# 3061MNNIC8 register map
File version: 1.0
Registers are 32-bit, access per field, reset 0x0 unless marked. A register's access mark holds for its fields unless they carry their own. Offsets are from the block's base; [hi:lo] are bit positions.

## EFC — HIEFC_COMMON_REGS peripheral interface
Base 0x14710000
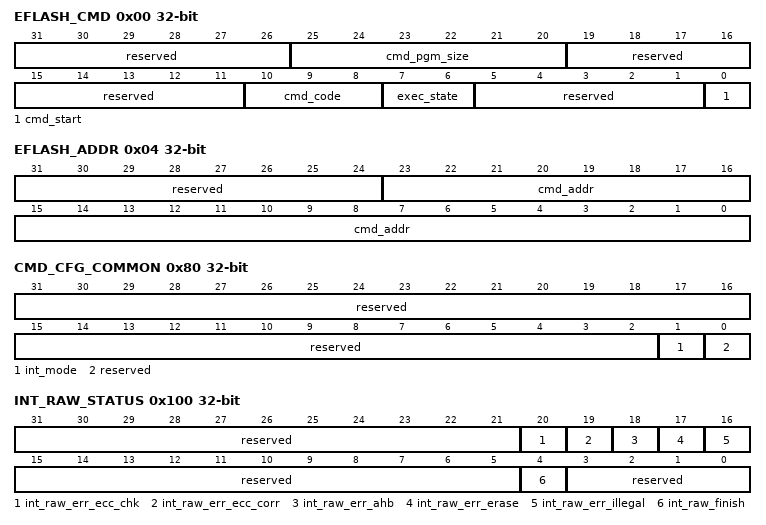
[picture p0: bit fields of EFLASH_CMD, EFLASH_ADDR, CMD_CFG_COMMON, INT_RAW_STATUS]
0x00 EFLASH_CMD — 命令寄存器。
  [31:26] reserved ro — 保留。
  [25:20] cmd_pgm_size rw — Program Size寄存器,Unit:Word（32bits）。 0x0: 2 ； 0x1: 4 ； 0x2: 8 ； … 0x0F:60； 0x10:64； others:非法值。 cmd_addr+cmd_pgm_size寻址范围不能跨越row（64Word），cmd_addr需要按64bit对齐。
  [19:11] reserved ro — 保留。
  [10:8] cmd_code rw — 操作字寄存器。 010: MAIN Program； 011: INFO Program； 100: MAIN Erase； 101: INFO Erase； 110: Mass Erase（Only Main区，不含INFO区）； others:无操作。
  [7:6] exec_state ro — CMD执行状态debug寄存器。 00（IDLE）:无操作或操作已完成； 01（RUNNING）:有操作在执行； 10（FINISH）:操作完成，但完成标示未清除(中断模式才生效)。
  [5:1] reserved ro — 保留。
  [0] cmd_start rw — CMD操作启动寄存器。 写1启动CMD操作； 写0无影响； 读1 CMD操作未完成； 读0 CMD操作完成或无操作。
0x04 EFLASH_ADDR — 地址寄存器。
  [31:24] reserved ro — 保留。
  [23:0] cmd_addr rw — Program或者Erase的起始地址寄存器，Unit:Byte（8bit）。 Main Region起始地址:0x00_0000； Information Region起始地址:0x80_0000。 注意：控制器自动忽略低2bit地址。
0x80 CMD_CFG_COMMON — CMD配置寄存器。
  [31:2] reserved ro — 保留。
  [1] int_mode rw — CMD操作方式控制寄存器。 0:轮询方式； 1:中断方式，此方式CMD操作完成后需要配置int_clr_finish清除完成标识，方可进行下一次操作。
  [0] reserved ro — 保留。
0x100 INT_RAW_STATUS ro — 中断原始状态寄存器。
  [31:21] reserved — 保留。
  [20] int_raw_err_ecc_chk — Main Region或Information Region读数据ECC检验错误原始中断寄存器。 0:无错误，或者读数据ECC检错功能未使能； 1:发生ECC检查错误。
  [19] int_raw_err_ecc_corr — Main Region或Information Region读数据ECC纠正错误原始中断寄存器。 0:无错误，或者读数据ECC纠错功能未使能； 1:发生无法纠正的ECC错误。
  [18] int_raw_err_ahb — ahb请求错误原始中断寄存器。 0:无错误； 1:ahb读请求地址超过MAIN Information Region范围或发生了ahb写请求。
  [17] int_raw_err_erase — 擦除错误原始中断状态寄存器。 0:擦除操作Verify成功； 1:擦除操作Verify失败。
  [16] int_raw_err_illegal — 非法CMD操作错误原始中断寄存器。 0:无错误； 1:存在CMD操作错误，具体错误，需要查询FLASH_STATUS寄存器。
  [15:5] reserved — 保留。
  [4] int_raw_finish — CMD操作完成原始中断寄存器。 0:无操作或者操作未完成； 1:操作已完成。
  [3:0] reserved — 保留。
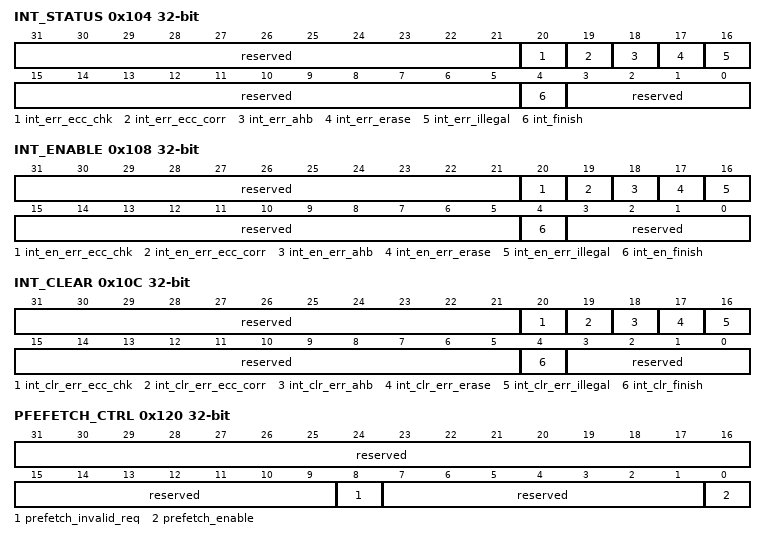
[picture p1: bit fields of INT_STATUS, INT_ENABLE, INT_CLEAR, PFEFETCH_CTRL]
0x104 INT_STATUS ro — 中断状态寄存器。
  [31:21] reserved
  [20] int_err_ecc_chk — Main Region或Information Region读数据ECC检验错误中断状态寄存器。 0：无错误，或者读数据ECC检错功能未使能 1：发生ECC检查错误
  [19] int_err_ecc_corr — Main Region或Information Region读数据ECC纠正错误中断状态寄存器。 0：无错误，或者读数据ECC纠错功能未使能 1：发生无法纠正的ECC错误
  [18] int_err_ahb — AHB请求错误中断状态寄存器。 0：无错误 1：AHB读请求地址超过Main Region或Information Region范围或发生了AHB写请求
  [17] int_err_erase — 擦除错误中断状态寄存器。 0:擦除操作Verify成功； 1:擦除操作Verify失败。
  [16] int_err_illegal — 非法CMD操作错误中断状态寄存器 0：无错误 1：存在CMD操作错误，具体错误，需要查询FLASH_STATUS寄存器
  [15:5] reserved
  [4] int_finish — CMD操作完成中断状态寄存器。 0：无操作或者操作未完成 1：操作已完成
  [3:0] reserved — 保留。
0x108 INT_ENABLE — 中断使能配置寄存器。
  [31:21] reserved ro — 保留。
  [20] int_en_err_ecc_chk rw — Main Region或Information Region读数据ECC检验错误中断使能寄存器。 0:不使能，上报原始中断，不上报中断状态，不上报CPU中断； 1:使能，上报原始中断，上报中断状态，上报CPU中断。
  [19] int_en_err_ecc_corr rw — Main Region或Information Region读数据ECC纠正错误中断使能寄存器。 0:不使能，上报原始中断，不上报中断状态，不上报CPU中断； 1:使能，上报原始中断，上报中断状态，上报CPU中断。
  [18] int_en_err_ahb rw — ahb请求错误中断使能寄存器。 0:不使能，上报原始中断，不上报中断状态，不上报CPU中断； 1:使能，上报原始中断，上报中断状态，上报CPU中断。
  [17] int_en_err_erase rw — 擦除错误中断使能寄存器。 0:不使能，上报原始中断，不上报中断状态，不上报CPU中断； 1:使能，上报原始中断，上报中断状态，上报CPU中断。
  [16] int_en_err_illegal rw — 非法CMD操作错误中断使能寄存器。 0:不使能，上报原始中断，不上报中断状态，不上报CPU中断； 1:使能，上报原始中断，上报中断状态，上报CPU中断。
  [15:5] reserved ro — 保留。
  [4] int_en_finish rw — CMD操作完成中断使能寄存器。 0:不使能，上报原始中断，不上报中断状态，不上报CPU中断； 1:使能，上报原始中断，上报中断状态，上报CPU中断。
  [3:0] reserved ro — 保留。
0x10C INT_CLEAR — 中断清除寄存器。
  [31:21] reserved ro — 保留。
  [20] int_clr_err_ecc_chk rw write-1-clears — Main Region或Information Region读数据ECC检验错误中断清除寄存器。 0:不清除； 1:清除原始中断与中断状态。
  [19] int_clr_err_ecc_corr rw write-1-clears — Main Region或Information Region读数据ECC纠正错误中断清除寄存器。 0:不清除； 1:清除原始中断与中断状态。
  [18] int_clr_err_ahb rw write-1-clears — ahb请求错误中断清除寄存器。 0:不清除； 1:清除原始中断与中断状态。
  [17] int_clr_err_erase rw write-1-clears — 擦除错误中断清除寄存器。 0:不清除； 1:清除原始中断与中断状态。
  [16] int_clr_err_illegal rw write-1-clears — 非法CMD操作错误中断清除寄存器。 0:不清除； 1:清除原始中断与中断状态。
  [15:5] reserved ro — 保留。
  [4] int_clr_finish rw write-1-clears — CMD操作完成中断清除寄存器。 0:不清除； 1:清除原始中断与中断状态。
  [3:0] reserved ro — 保留。
0x120 PFEFETCH_CTRL — 预取控制寄存器。
  [31:9] reserved ro — 保留。
  [8] prefetch_invalid_req rw — Cache数据无效请求控制寄存器。 写0:无效； 写1:请求prefetch_invalid，逻辑完成invalid后自动清除该bit； 读0:最近一次invalid请求已完成； 读1:最近一次invalid请求未完成。
  [7:1] reserved ro — 保留。
  [0] prefetch_enable rw — 预取使能控制寄存器。 0:预取使能关闭； 1:每次AHB传输完成尾地址向前预取16byte数据（以8byte对齐）。
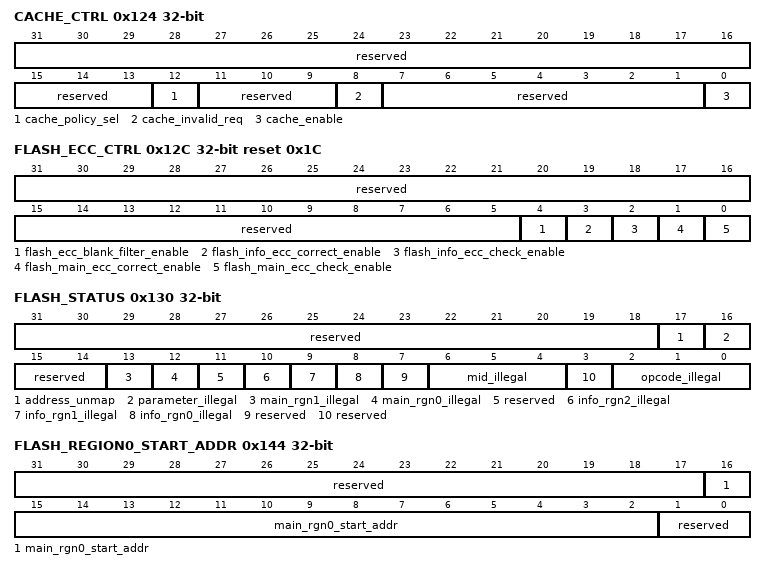
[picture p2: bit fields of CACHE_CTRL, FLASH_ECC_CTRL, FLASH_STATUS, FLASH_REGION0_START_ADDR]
0x124 CACHE_CTRL — Cache控制寄存器。
  [31:13] reserved ro — 保留。
  [12] cache_policy_sel rw — cache策略选择控制寄存器。 0:Normal Cache； 1:Branch Cache。
  [11:9] reserved ro — 保留。
  [8] cache_invalid_req rw — Cache数据无效请求控制寄存器 。 写1:请求Cache invalid，逻辑完成invalid后自动清除该bit； 写0无效； 读0:最近一次invalid请求已完成； 读1:最近一次invalid请求未完成。
  [7:1] reserved ro — 保留。
  [0] cache_enable rw — Cache使能控制寄存器。 0:Cache使能关闭； 1:Cache使能打开，AHB传输数据将会查询Cache，Cache Hit则数据从Cache获取，Cache miss则数据从eFlash获取，并将此地址数据缓存进入Cache。
0x12C FLASH_ECC_CTRL reset 0x1C — Flash ECC检错纠错使能控制寄存器。
  [31:5] reserved ro — 保留。
  [4] flash_ecc_blank_filter_enable rw — Flash未编程区域ECC屏蔽过滤使能控制（72bit全1判断为未编程区域）。 0:不使能此功能，所有read访问数据都根据flash_ecc_correct_enable、flash_ecc_check_enable配置进行相应的ECC检查或者纠正； 1:使能此功能，检查read访问数据内容，只有非全1（72bit）数据根据flash_ecc_correct_enable、flash_ecc_check_enable配置进行相应的ECC检查或者纠正。
  [3] flash_info_ecc_correct_enable rw — Flash Information region ECC纠错功能控制。 0:回读数据发生错误时，不进行ECC纠错； 1:回读数据发生1bit错误时，进行ECC纠错。
  [2] flash_info_ecc_check_enable rw — Flash Information region 检错使能控制（Program 强制ECC打开）。 0:回读数据不进行ECC检查； 1:回读数据进行ECC检查。
  [1] flash_main_ecc_correct_enable rw — Flash Main region ECC纠错功能控制。 0:回读数据发生错误时，不进行ECC纠错； 1:回读数据发生1bit错误时，进行ECC纠错。
  [0] flash_main_ecc_check_enable rw — Flash Main region检错使能控制（Program 强制ECC打开）。 0:回读数据不进行ECC检查； 1:回读数据进行ECC检查。
0x130 FLASH_STATUS ro — CMD操作FLASH状态寄存器。
  [31:18] reserved — 保留。
  [17] address_unmap — cmd操作地址是否越界指示寄存器。 0:无错误； 1:地址越界错误。
  [16] parameter_illegal — cmd操作参数是否有效指示寄存器。 0:无错误； 1:操作参数错误。
  [15:14] reserved — 保留。
  [13] main_rgn1_illegal — cmd操作main region1是否发生非法访问指示寄存器。 0:无错误； 1:Region1发生非法访问。
  [12] main_rgn0_illegal — cmd操作main region0是否发生非法访问指示寄存器。 0:无错误； 1:Region0 发送非法访问。
  [11] reserved — 保留。
  [10] info_rgn2_illegal — cmd操作info region2是否发生非法访问指示寄存器。 0:无错误； 1:info_rgn2区发生非法访问。
  [9] info_rgn1_illegal — cmd操作info region1是否发生非法访问指示寄存器。 0:无错误； 1:info_rgn1区发生非法访问。
  [8] info_rgn0_illegal — cmd操作main region0是否发生非法访问指示寄存器。 0:无错误； 1:info_rgn0区发生非法访问。
  [7] reserved — 保留。
  [6:4] mid_illegal — 发生非法访问时，cmd寄存器非法mid value。
  [3] reserved — 保留。
  [2:0] opcode_illegal — 发生非法访问时，cmd寄存器非法opcode value。
0x138 AHB_ERR_ADDR ro — AHB错误请求地址记录寄存器。
  [31:0] ahb_err_address — int_raw_err_ahb发生时，记录第一次发生ahb错误访问的地址信息，包括越界与ahb 写操作。 配置中断清除寄存器int_clr_err_ahb时，该寄存器清0，并开始记录下一次错误请求地址信息。
0x144 FLASH_REGION0_START_ADDR — MAIN REGION0起始地址。
  [31:17] reserved ro — 保留。
  [16:2] main_rgn0_start_addr rw — main_rgn0起始地址寄存器，Unit:Word（32bit）。
  [1:0] reserved ro — 保留。
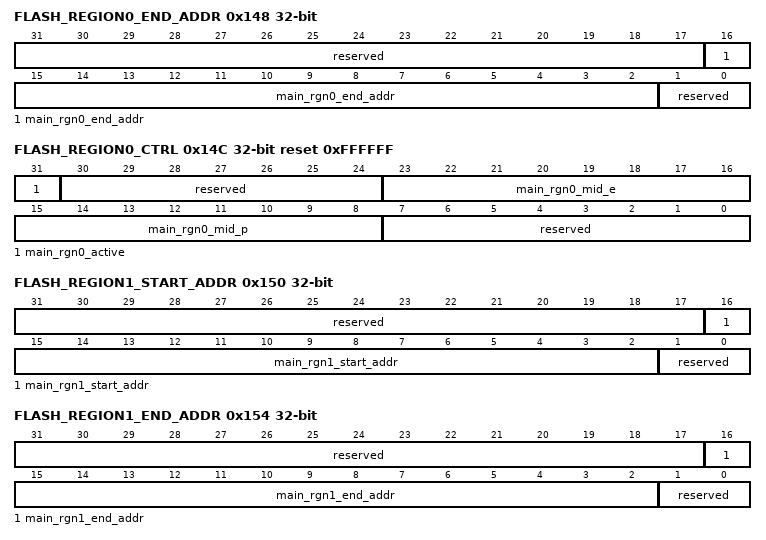
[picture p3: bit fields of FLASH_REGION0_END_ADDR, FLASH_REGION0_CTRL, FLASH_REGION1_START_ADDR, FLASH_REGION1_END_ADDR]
0x148 FLASH_REGION0_END_ADDR — MAIN REGION0结束地址。
  [31:17] reserved ro — 保留。
  [16:2] main_rgn0_end_addr rw — main_rgn0结束地址寄存器，Unit:Word（32bit）。
  [1:0] reserved ro — 保留。
0x14C FLASH_REGION0_CTRL reset 0xFFFFFF — MAIN REGION0控制寄存器。
  [31] main_rgn0_active rw — 是否激活区域访问控制寄存器。 0:不激活； 1:激活。
  [30:24] reserved ro — 保留。
  [23:16] main_rgn0_mid_e rw — 允许对main_rgn0擦除操作的mid。 bit[7:0]分别标识mid为7-0的master是否允许擦除操作， 0：禁止； 1：允许。
  [15:8] main_rgn0_mid_p rw — 允许对main_rgn0编程操作的mid。 bit[7:0]分别标识mid为7-0的master是否允许编程操作， 0：禁止； 1：允许。
  [7:0] reserved ro — 保留。
0x150 FLASH_REGION1_START_ADDR — MAIN REGION1起始地址。
  [31:17] reserved ro — 保留。
  [16:2] main_rgn1_start_addr rw — main_rgn1起始地址寄存器，Unit:Word（32bit）。
  [1:0] reserved ro — 保留。
0x154 FLASH_REGION1_END_ADDR — MAIN REGION1结束地址。
  [31:17] reserved ro — 保留。
  [16:2] main_rgn1_end_addr rw — main_rgn1结束地址寄存器，Unit:Word（32bit）。
  [1:0] reserved ro — 保留。
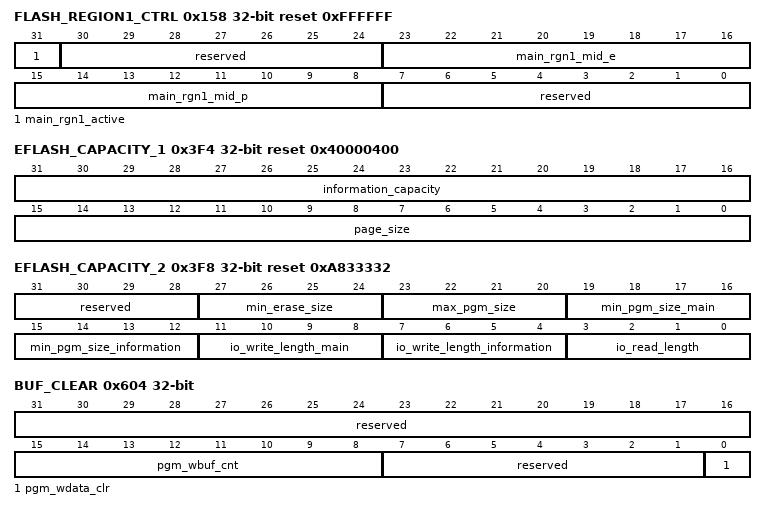
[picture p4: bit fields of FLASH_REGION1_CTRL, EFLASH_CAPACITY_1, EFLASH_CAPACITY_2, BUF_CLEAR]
0x158 FLASH_REGION1_CTRL reset 0xFFFFFF — MAIN REGION1控制寄存器。
  [31] main_rgn1_active rw — 是否激活区域访问控制寄存器。 0:不激活； 1:激活。
  [30:24] reserved ro — 保留。
  [23:16] main_rgn1_mid_e rw — 允许对main_rgn1擦除操作的mid。 bit[7:0]分别标识mid为7-0的master是否允许擦除操作。 0：禁止； 1：允许。
  [15:8] main_rgn1_mid_p rw — 允许对main_rgn1编程操作的mid。 bit[7:0]分别标识mid为7-0的master是否允许编程操作， 0：禁止； 1：允许。
  [7:0] reserved ro — 保留。
0x200 MAGIC_LOCK rw — CMD操作魔术字保护寄存器。
  [31:0] magic_lock — 写入0xFEDC_BA98，魔术字解锁，CMD相关操作寄存器写入权限打开， 写入其他数值，魔术字锁定，CMD相关操作寄存器写入权限关闭。 读出0xFEDC_BA98表示解锁，读出0表示锁定。 默认为锁定状态。 CMD相关操作寄存器包括:FLASH_CMD、FLASH_ADDR、FLASH_WDATA、FLASH_RDATA。
0x3F0 EFLASH_CAPACITY_0 rw reset 0x20000 — 模块信息寄存器0。
  [31:0] main_capacity — Main Region容量指示寄存器，Unit:Byte。
0x3F4 EFLASH_CAPACITY_1 ro reset 0x40000400 — 模块信息寄存器1。
  [31:16] information_capacity — Information Region容量指示寄存器，Unit:Byte。
  [15:0] page_size — eFlash Page容量指示寄存器，Unit:Byte。
0x3F8 EFLASH_CAPACITY_2 ro reset 0xA833332 — 模块信息寄存器2。
  [31:28] reserved — 保留。
  [27:24] min_erase_size — 最小擦除size（2**n）unit:Byte。 1KB。
  [23:20] max_pgm_size — 连续编程最大size（2**n） Byte。 256Bytes。
  [19:16] min_pgm_size_main — main region最小编程size（2**n） Byte。 8Bytes。
  [15:12] min_pgm_size_information — Information region最小编程size（2**n） Byte。 8Bytes。
  [11:8] io_write_length_main — 写main region IO size （2**n) Byte（不算ECC bit）。 8Bytes。
  [7:4] io_write_length_information — 写info region IO size （2**n) Byte（不算ECC bit）。 8Bytes。
  [3:0] io_read_length — 读IO size （2**n） Byte（不算ECC bit）。 4bytes。
0x400 PGM_WDATA wo — 编程数据寄存器。
  [31:0] pgm_wdata — 编程数据Buffer寄存器。 0x400-0x5FC，都映射到同一写数据寄存器； 写0x400-0x5FC任意一个寄存器一次，写数据buffer数据增加一个Word（32bits），此buffer数据先进先出。
0x604 BUF_CLEAR — 编程数据Buffer清理寄存器。
  [31:16] reserved ro — 保留。
  [15:8] pgm_wbuf_cnt ro — 编程数据buffer当前存量数据size指示寄存器 unit:Word(32bit)。
  [7:1] reserved ro — 保留。
  [0] pgm_wdata_clr rw write-1-clears — 编程数据Buffer数据清除控制寄存器。 写1:清除当前Buffer中残留数据； 写0:无效果。
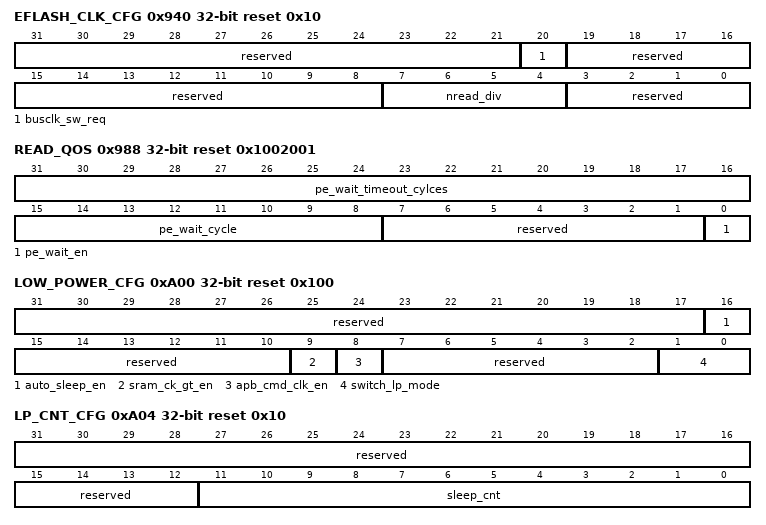
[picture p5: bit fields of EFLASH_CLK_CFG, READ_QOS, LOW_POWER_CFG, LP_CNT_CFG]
0x940 EFLASH_CLK_CFG reset 0x10 — 时钟分频寄存器
  [31:21] reserved ro — 保留。
  [20] busclk_sw_req rw — nread_div是否切换完成配置查询寄存器。写1后触发电路进行切换，回读判断是否切换完成。 读0:切换完成； 读1:切换未完成。
  [19:8] reserved ro — 保留。
  [7:4] nread_div rw — Flash Read，系统总线主时钟与 Flash 时钟比值(n+1)。 0x0:1分频； 0x1:2分频； …… 0xF:16分频。
  [3:0] reserved ro — 保留。
0x988 READ_QOS reset 0x1002001 — 读QOS配置寄存器。
  [31:16] pe_wait_timeout_cylces rw — pe_wait 使能后，PE(Program and Erase)请求被阻塞 cycle 超过pe_wait_timeout_cylces+pe_wait_cycles，提高PE请求优先级，优先响应PE请求。
  [15:8] pe_wait_cycle rw — 为避免稀疏的Read操作被PE操作阻塞，在完成Read操作后维持pe_wait_cycle个cycle(总线时钟)，在此期间阻塞PE请求。 0表示不阻塞。
  [7:1] reserved ro — 保留。
  [0] pe_wait_en rw — PE_wait 功能使能。0:不使能；1:使能，Read 结束后，在 pe_wait_cycle时间内，阻塞 PE 请求，在此 cycle 内入股有新的 Read 请求，会优先响应 Read。
0xA00 LOW_POWER_CFG reset 0x100 — 低功耗控制寄存器。
  [31:17] reserved ro — 保留。
  [16] auto_sleep_en rw — 自动休眠低功耗功能控制。0:关闭；1:开启，当 Main 状态机 IDLE 时间超过sleep_cnt 阈值时，逻辑自动控制 Macro进入 DPD(Deep Power Down)模式。
  [15:10] reserved ro — 保留。
  [9] sram_ck_gt_en rw — 内部SRAM时钟动态门控使能控制。0:SRAM 时钟常开；1:SRAM 时钟动态门控，需要读写时逻辑自动打开，读写结束自动关闭。
  [8] apb_cmd_clk_en rw — Flash CMD 相关逻辑时钟使能控制。 0:关闭 Erase/Program 相关数字逻辑时钟； 1:打开 Erase/Program 相关数字逻辑时钟。
  [7:2] reserved ro — 保留。
  [1:0] switch_lp_mode rw — 软件直接控制低功耗切换。 00:操作完成； 01:唤醒； 10:睡眠； 11:保留。 软件写入非0值，触发状态跳转，跳转完成寄存器自动回到0。
0xA04 LP_CNT_CFG reset 0x10 — 低功耗计数控制寄存器。
  [31:12] reserved ro — 保留。
  [11:0] sleep_cnt rw — 自动低功耗 IDLE 等待时间(us 时钟计数)。不可为 0，最大 2.6ms。默认:16us。
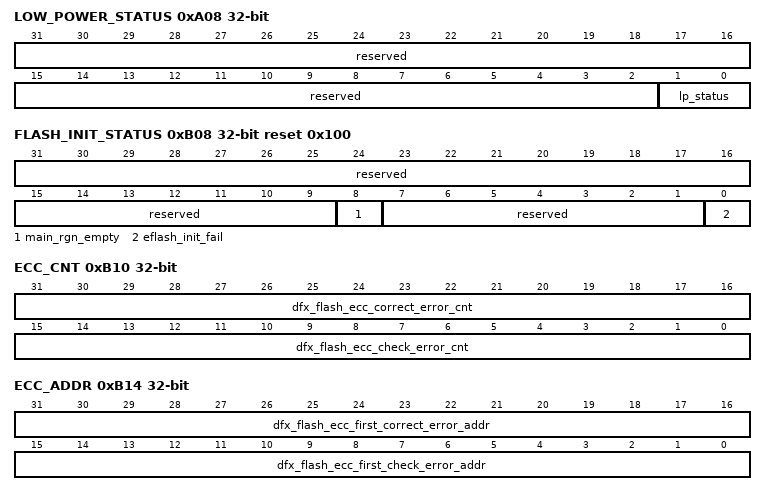
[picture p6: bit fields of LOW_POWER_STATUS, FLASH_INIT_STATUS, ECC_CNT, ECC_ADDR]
0xA08 LOW_POWER_STATUS ro — 低功耗状态寄存器。
  [31:2] reserved — 保留。
  [1:0] lp_status — 控制器低功耗状态指示寄存器。 00:正常工作； 01:初始化； 10:睡眠； 11:下电。
0xB08 FLASH_INIT_STATUS ro reset 0x100 — 初始化状态寄存器。
  [31:9] reserved — 保留。
  [8] main_rgn_empty — Main Region第一个地址是否被编程执行寄存器。 0:第一个地址被编程过； 1:第一个地址未被编程过。
  [7:1] reserved — 保留。
  [0] eflash_init_fail — Flash初始化失败标志位。
0xB10 ECC_CNT ro — ECC错误计数寄存器。
  [31:16] dfx_flash_ecc_correct_error_cnt — Main Region 或 Information Region 读数据发生 ECC 纠错失败次数，每次对应一个64bit。软件清除 int_raw_err_ecc_corr 原始中断后，重新统计。
  [15:0] dfx_flash_ecc_check_error_cnt — Main Region 或 Information Region 读数据发生 ECC 检查错误次数，每次对应一个64bit。软件清除 int_raw_err_ecc_chk 原始中断后，重新统计。
0xB14 ECC_ADDR ro — ECC错误地址寄存器。
  [31:16] dfx_flash_ecc_first_correct_error_addr — 读 Flash 第一次发生 ECC 检查错误的物理地址，Unit:64bit。软件清除 int_raw_err_ecc_corr 原始中断后，重新统计。最高 2 位表示区域:00:表示 Main Region；01:表示 Information Region。
  [15:0] dfx_flash_ecc_first_check_error_addr — 读 Flash 第一次发生 ECC 检查错误的物理地址，Unit:64bit。软件清除 int_raw_err_ecc_chk 原始中断后，重新统计。最高 2 位表示区域：00：表示 Main Region；01：表示 Information Region。
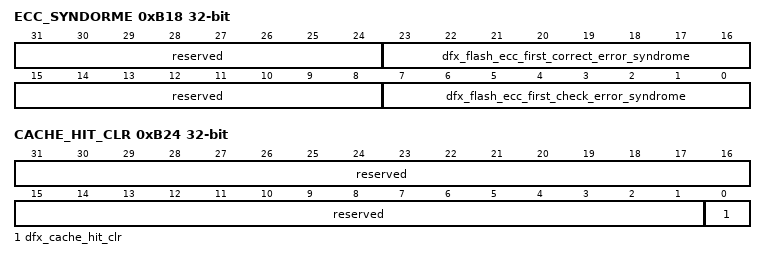
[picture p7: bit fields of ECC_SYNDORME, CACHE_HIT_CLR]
0xB18 ECC_SYNDORME ro — ECC错误码寄存器。
  [31:24] reserved — 保留。
  [23:16] dfx_flash_ecc_first_correct_error_syndrome — 读 Flash 第一次发生 ECC 纠错错误的错误字符。软件清除 int_raw_err_ecc_corr 原始中断后，重新统计。
  [15:8] reserved — 保留。
  [7:0] dfx_flash_ecc_first_check_error_syndrome — 读 Flash 第一次发生 ECC 检查错误的错误字符。软件清除 int_raw_err_ecc_chk 原始中断后，重新统计。
0xB24 CACHE_HIT_CLR — Cache命中率清除寄存器。
  [31:1] reserved ro — 保留。
  [0] dfx_cache_hit_clr rw write-1-clears — dfx_cache_lookup_cnt 与dfx_cache_hit_cnt 计数器清零控制寄存器。写 0 无效果；写 1 dfx_cache_lookup_cnt 与dfx_cache_hit_cnt 清零。
0xB28 CACHE_LOOKUP_CNT ro — Cache查询次数寄存器。
  [31:0] dfx_cache_lookup_cnt — Cache 查询次数统计计数器。Unit：次。
0xB2C CACHE_HIT_CNT ro — Cache命中次数寄存器。
  [31:0] dfx_cache_hit_cnt — cache 查询命中次数统计计数器。Unit：次。
